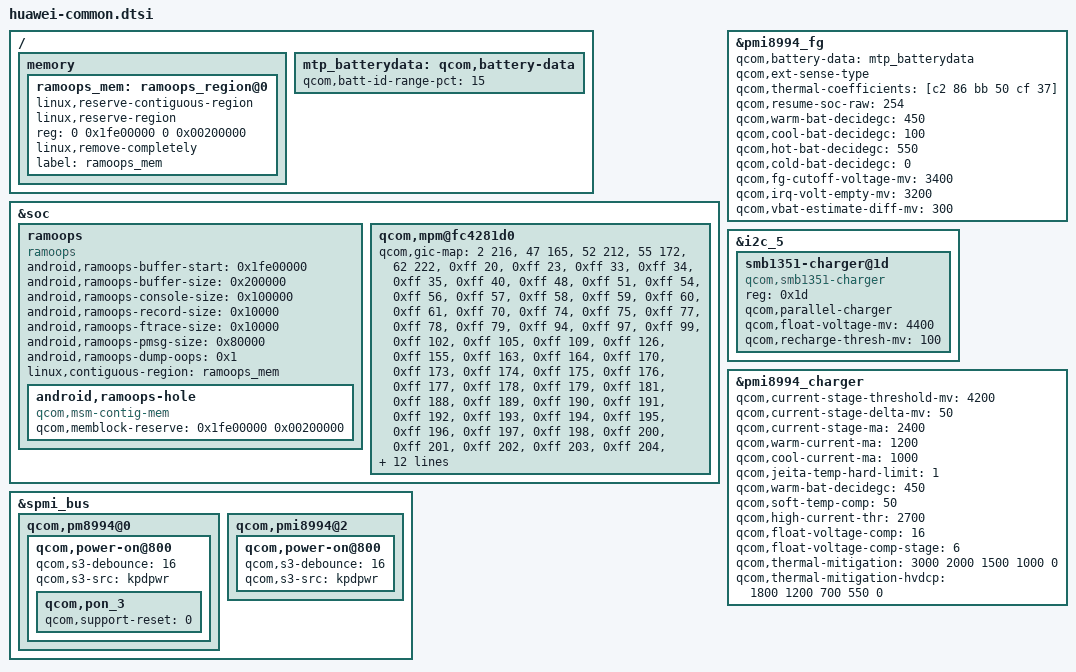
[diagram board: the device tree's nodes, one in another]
/* Copyright (c) 2015, The Linux Foundation. All rights reserved.
 *
 * This program is free software; you can redistribute it and/or modify
 * it under the terms of the GNU General Public License version 2 and
 * only version 2 as published by the Free Software Foundation.
 *
 * This program is distributed in the hope that it will be useful,
 * but WITHOUT ANY WARRANTY; without even the implied warranty of
 * MERCHANTABILITY or FITNESS FOR A PARTICULAR PURPOSE.  See the
 * GNU General Public License for more details.
 */

/ {
	memory {
		#address-cells = <2>;
		#size-cells = <2>;

		ramoops_mem: ramoops_region@0 {
			linux,reserve-contiguous-region;
			linux,reserve-region;
			reg = <0 0x1fe00000 0 0x00200000>;
			linux,remove-completely;
			label = "ramoops_mem";
		};
	};
};

&soc {
	ramoops {
		compatible = "ramoops";
		status = "ok";

		android,ramoops-buffer-start = <0x1fe00000>;
		android,ramoops-buffer-size = <0x200000>;
		android,ramoops-console-size = <0x100000>;
		android,ramoops-record-size = <0x10000>;
		android,ramoops-ftrace-size = <0x10000>;
		android,ramoops-pmsg-size = <0x80000>;
		android,ramoops-dump-oops = <0x1>;
		linux,contiguous-region = <&ramoops_mem>;
		android,ramoops-hole {
			compatible = "qcom,msm-contig-mem";
			qcom,memblock-reserve = <0x1fe00000 0x00200000>;
		};
	};

	qcom,mpm@fc4281d0 {
		qcom,gic-map = <2 216>, /* tsens_upper_lower_int */
			<47 165>, /* usb30_hs_phy_irq */
			<52 212>, /* lfps_rxterm_irq for pwr_event_irq */
			<55 172>, /* usb1_hs_async_wakeup_irq */
			<62 222>, /* ee0_krait_hlos_spmi_periph_irq */
			<0xff 20>,  /* arch_timer */
			<0xff 23>,  /* ARM64 Single-Bit Error PMU IRQ */
			<0xff 33>,  /* APCC_qgicL2PerfMonIrptReq */
			<0xff 34>,  /* APCC_qgicL2ErrorIrptReq */
			<0xff 35>,  /* WDT_barkInt */
			<0xff 40>,  /* qtimer_phy_irq */
			<0xff 48>,  /* cpr */
			<0xff 51>,  /* cpr */
			<0xff 54>,  /* CCI error IRQ */
			<0xff 56>,  /* modem_watchdog */
			<0xff 57>,  /* mss_to_apps_irq(0) */
			<0xff 58>,  /* mss_to_apps_irq(1) */
			<0xff 59>,  /* mss_to_apps_irq(2) */
			<0xff 60>,  /* mss_to_apps_irq(3) */
			<0xff 61>,  /* mss_a2_bam_irq */
			<0xff 70>,  /* iommu_pmon_nonsecure_irq */
			<0xff 74>,  /* osmmu_CIrpt[1] */
			<0xff 75>,  /* osmmu_CIrpt[0] */
			<0xff 77>,  /* osmmu_CIrpt[0] */
			<0xff 78>,  /* osmmu_CIrpt[0] */
			<0xff 79>,  /* osmmu_CIrpt[0] */
			<0xff 94>,  /* osmmu_CIrpt[0] */
			<0xff 97>,  /* iommu_nonsecure_irq */
			<0xff 99>,  /* msm_iommu_pmon_nonsecure_irq */
			<0xff 102>,  /* osmmu_CIrpt[1] */
			<0xff 105>, /* iommu_pmon_nonsecure_irq */
			<0xff 109>,  /* ocmem_dm_nonsec_irq */
			<0xff 126>,  /* bam_irq[0] */
			<0xff 155>,  /* sdcc_irq[0] */
			<0xff 163>,  /* usb30_ee1_irq */
			<0xff 164>,  /* sps */
			<0xff 170>,  /* sdcc_pwr_cmd_irq */
			<0xff 173>, /* o_wcss_apss_smd_hi */
			<0xff 174>, /* o_wcss_apss_smd_med */
			<0xff 175>, /* o_wcss_apss_smd_low */
			<0xff 176>, /* o_wcss_apss_smsm_irq */
			<0xff 177>, /* o_wcss_apss_wlan_data_xfer_done */
			<0xff 178>, /* o_wcss_apss_wlan_rx_data_avail */
			<0xff 179>, /* o_wcss_apss_asic_intr */
			<0xff 181>, /* wcnss watchdog */
			<0xff 188>, /* lpass_irq_out_apcs(0) */
			<0xff 189>, /* lpass_irq_out_apcs(1) */
			<0xff 190>, /* lpass_irq_out_apcs(2) */
			<0xff 191>, /* lpass_irq_out_apcs(3) */
			<0xff 192>, /* lpass_irq_out_apcs(4) */
			<0xff 193>, /* lpass_irq_out_apcs(5) */
			<0xff 194>, /* lpass_irq_out_apcs(6) */
			<0xff 195>, /* lpass_irq_out_apcs(7) */
			<0xff 196>, /* lpass_irq_out_apcs(8) */
			<0xff 197>, /* lpass_irq_out_apcs(9) */
			<0xff 198>, /* coresight-tmc-etr interrupt */
			<0xff 200>, /* rpm_ipc(4) */
			<0xff 201>, /* rpm_ipc(5) */
			<0xff 202>, /* rpm_ipc(6) */
			<0xff 203>, /* rpm_ipc(7) */
			<0xff 204>, /* rpm_ipc(24) */
			<0xff 205>, /* rpm_ipc(25) */
			<0xff 206>, /* rpm_ipc(26) */
			<0xff 207>, /* rpm_ipc(27) */
			<0xff 211>, /* usb_dwc3_otg */
			<0xff 212>,  /* msm_dwc3 */
			<0xff 215>,  /* fc388000.qcom,cpu-bwmon */
			<0xff 224>,  /* spdm_bw_hyp */
			<0xff 240>, /* summary_irq_kpss */
			<0xff 261>,  /* msm_iommu_global_cfg */
			<0xff 263>,  /* msm_iommu_global_client */
			<0xff 268>, /* bam_irq[1] */
			<0xff 270>, /* bam_irq[0] */
			<0xff 271>, /* bam_irq[0] */
			<0xff 272>,  /* msm_iommu_secure_irq */
			<0xff 273>,  /* msm_iommu_nonsecure_irq */
			<0xff 275>,  /* int_msi */
			<0xff 283>,  /* int_pls_err */
			<0xff 284>,  /* int_aer_legacy */
			<0xff 286>,  /* int_pls_link_down */
			<0xff 298>,  /* msm_iommu_nonsecure_irq */
			<0xff 302>,  /* coresight-tmc-etr */
			<0xff 303>,  /* int_msi */
			<0xff 310>,  /* int_pls_err */
			<0xff 311>,  /* int_aer_legacy */
			<0xff 313>,  /* int_pls_link_down */
			<0xff 329>,  /* sps */
			<0xff 332>, /* sps */
			<0xff 333>, /* ipa */
			<0xff 348>,  /* fd878000.qcom,fd */
			<0xff 350>,  /* msm_iommu_nonsecure_irq */
			<0xff 360>,  /* ARM64 primary DBE IRQ */
			<0xff 361>,  /* ARM64 secondary DBE IRQ */
			<0xff 362>,  /* ARM64 primary ext IRQ */
			<0xff 363>,  /* ARM64 secondary ext IRQ */
			<0xff 364>, /* lmh_interrupt */
			<0xff 65>, /* kgsl-3d0 */
			<0xff 115>, /* MDSS */
			<0xff 128>, /* i2c-msm-v2-irq */
			<0xff 131>, /* f9927000.spi */
			<0xff 132>, /* i2c-msm-v2-irq */
			<0xff 133>, /* i2c-msm-v2-irq */
			<0xff 137>, /* i2c-msm-v2-irq */
			<0xff 140>, /* unknown */
			<0xff 157>, /* mmc1 */
			<0xff 253>; /* f98a4900.sdhci */
	};
};

/* battery related change */
/ {
	mtp_batterydata: qcom,battery-data {
		qcom,batt-id-range-pct = <15>;
		#include "batterydata-itech-3000mah.dtsi"
		#include "Sunwoda_ATL_3450mAh_battery_profile.dtsi"
		#include "SCUD_SONY_3450mAh_battery_profile.dtsi"
	};
};

&pmi8994_fg {
	qcom,battery-data = <&mtp_batterydata>;
	qcom,ext-sense-type;
	qcom,thermal-coefficients = [c2 86 bb 50 cf 37];
	qcom,resume-soc-raw = <254>;
	qcom,warm-bat-decidegc = <450>;
	qcom,cool-bat-decidegc = <100>;
	qcom,hot-bat-decidegc = <550>;
	qcom,cold-bat-decidegc = <0>;
	qcom,fg-cutoff-voltage-mv = <3400>;
	qcom,irq-volt-empty-mv = <3200>;
	qcom,vbat-estimate-diff-mv = <300>;
};

&i2c_5 {
	smb1351-charger@1d {
		compatible = "qcom,smb1351-charger";
		reg = <0x1d>;
		qcom,parallel-charger;
		qcom,float-voltage-mv = <4400>;
		qcom,recharge-thresh-mv = <100>;
	};
};

&pmi8994_charger {
	qcom,current-stage-threshold-mv = <4200>;
	qcom,current-stage-delta-mv = <50>;
	qcom,current-stage-ma = <2400>;
	qcom,warm-current-ma = <1200>;
	qcom,cool-current-ma = <1000>;
	qcom,jeita-temp-hard-limit = <1>;
	qcom,warm-bat-decidegc = <450>;
	qcom,soft-temp-comp = <50>;
	qcom,high-current-thr = <2700>;
	qcom,float-voltage-comp = <16>;
	qcom,float-voltage-comp-stage = <6>;
	qcom,thermal-mitigation = <3000 2000 1500 1000 0>;
	qcom,thermal-mitigation-hvdcp = <1800 1200 700 550 0>;
};

&spmi_bus {
	qcom,pm8994@0 {
		qcom,power-on@800 {
			qcom,s3-debounce = <16>;
			qcom,s3-src = "kpdpwr";
			qcom,pon_3 {
				qcom,support-reset = <0>;
			};
		};
	};

	qcom,pmi8994@2 {
		qcom,power-on@800 {
			qcom,s3-debounce = <16>;
			qcom,s3-src = "kpdpwr";
		};
	};
};

#include "huawei-led.dtsi"
